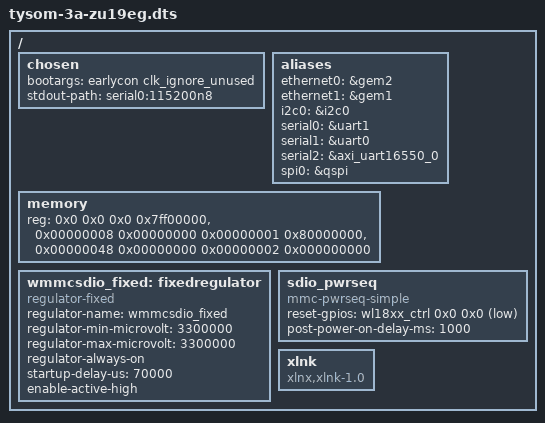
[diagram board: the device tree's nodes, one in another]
/*
 * CAUTION: This file is automatically generated by Xilinx.
 * Version:  
 * Today is: Thu Oct 25 11:07:18 2018
 */


/dts-v1/;
/include/ "zynqmp.dtsi"
/include/ "zynqmp-clk-ccf.dtsi"
/include/ "pl.dtsi"
/include/ "pcw.dtsi"
/ {
	chosen {
		bootargs = "earlycon clk_ignore_unused";
		stdout-path = "serial0:115200n8";
	};
	aliases {
		ethernet0 = &gem2;
		ethernet1 = &gem1;
		i2c0 = &i2c0;
		serial0 = &uart1;
		serial1 = &uart0;
		serial2 = &axi_uart16550_0;
		spi0 = &qspi;
	};
	memory {
		device_type = "memory";
		reg = <0x0 0x0 0x0 0x7ff00000>, <0x00000008 0x00000000 0x00000001 0x80000000>, <0x00000048 0x00000000 0x00000002 0x000000000>;
		//reg = <0x0 0x0 0x0 0x7ff00000>, <0x00000008 0x00000000 0x00000001 0x80000000>;
		
	};
	wmmcsdio_fixed: fixedregulator {
		compatible = "regulator-fixed";
		regulator-name = "wmmcsdio_fixed";
		regulator-min-microvolt = <3300000>;
		regulator-max-microvolt = <3300000>;
		//gpio = <&wl18xx_ctrl 0x0 0x0 0x0>;
		regulator-always-on;
		startup-delay-us = <70000>;
		enable-active-high;
	};
	
	sdio_pwrseq: sdio_pwrseq {
		compatible = "mmc-pwrseq-simple";
		reset-gpios = <&wl18xx_ctrl 0x0 0x0 0x1>;
		post-power-on-delay-ms = <1000>;
	};

	xlnk {
		compatible = "xlnx,xlnk-1.0";
	};
};
